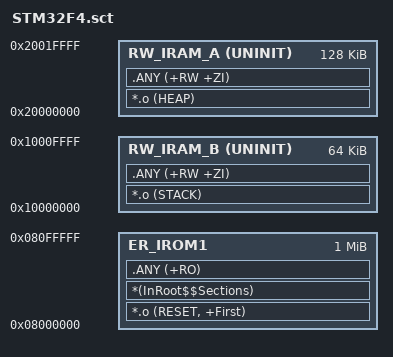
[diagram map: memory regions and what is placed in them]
; *************************************************************
; *** Scatter-Loading Description File generated by uVision ***
; *************************************************************

LR_IROM1 0x08000000 0x00100000  {    ; load region size_region
  ER_IROM1 0x08000000 0x00100000  {  ; load address = execution address
   *.o (RESET, +First)
   *(InRoot$$Sections)              ; no label available im assembler
   .ANY (+RO)
  }
  RW_IRAM_A 0x20000000 UNINIT 0x00020000  {
   *.o (HEAP)
   .ANY (+RW +ZI)
  }
  RW_IRAM_B 0x10000000 UNINIT 0x00010000  {  ; RW data
   *.o (STACK)
   .ANY (+RW +ZI)
  }
}
